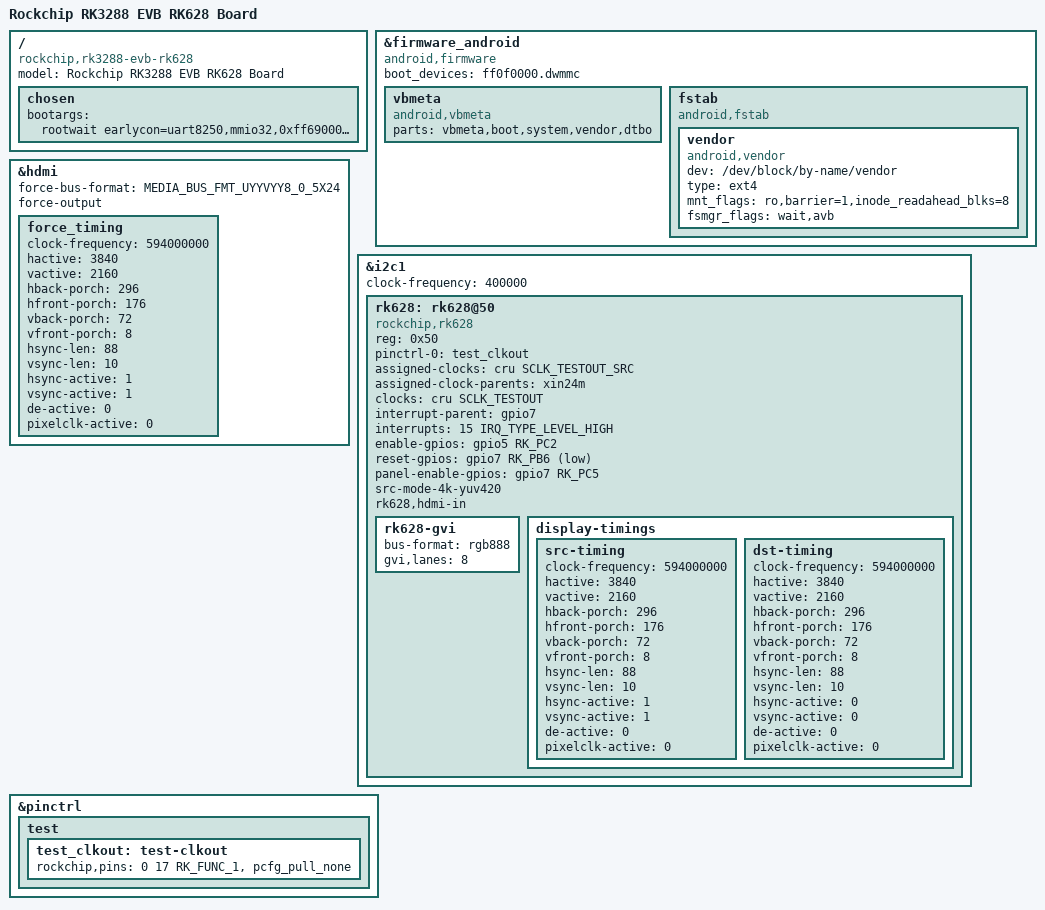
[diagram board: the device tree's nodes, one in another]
// SPDX-License-Identifier: (GPL-2.0+ OR MIT)
// Copyright (c) 2020 Fuzhou Rockchip Electronics Co., Ltd

/dts-v1/;
#include "rk3288-evb-rk628.dtsi"

/ {
	model = "Rockchip RK3288 EVB RK628 Board";
	compatible = "rockchip,rk3288-evb-rk628", "rockchip,rk3288";

	chosen {
		bootargs = "rootwait earlycon=uart8250,mmio32,0xff690000 vmalloc=496M swiotlb=1 console=ttyFIQ0 androidboot.baseband=N/A androidboot.veritymode=enforcing androidboot.hardware=rk30board androidboot.console=ttyFIQ0 init=/init kpti=0";
	};
};

&firmware_android {
	compatible = "android,firmware";
	boot_devices = "ff0f0000.dwmmc";

	vbmeta {
		compatible = "android,vbmeta";
		parts = "vbmeta,boot,system,vendor,dtbo";
	};

	fstab {
		compatible = "android,fstab";

		vendor {
			compatible = "android,vendor";
			dev = "/dev/block/by-name/vendor";
			type = "ext4";
			mnt_flags = "ro,barrier=1,inode_readahead_blks=8";
			fsmgr_flags = "wait,avb";
		};
	};
};

&hdmi {
	status = "okay";
	force-bus-format = <MEDIA_BUS_FMT_UYYVYY8_0_5X24>;
	force-output;
	force_timing {
		clock-frequency = <594000000>;
		hactive = <3840>;
		vactive = <2160>;
		hback-porch = <296>;
		hfront-porch = <176>;
		vback-porch = <72>;
		vfront-porch = <8>;
		hsync-len = <88>;
		vsync-len = <10>;
		hsync-active = <1>;
		vsync-active = <1>;
		de-active = <0>;
		pixelclk-active = <0>;
	};
};

&i2c1 {
	clock-frequency = <400000>;
	status = "okay";

	rk628: rk628@50 {
		compatible = "rockchip,rk628";
		reg = <0x50>;
		pinctrl-names = "default";
		pinctrl-0 = <&test_clkout>;
		assigned-clocks = <&cru SCLK_TESTOUT_SRC>;
		assigned-clock-parents = <&xin24m>;
		clocks = <&cru SCLK_TESTOUT>;
		clock-names = "soc_24M";
		interrupt-parent = <&gpio7>;
		interrupts = <15 IRQ_TYPE_LEVEL_HIGH>;
		enable-gpios = <&gpio5 RK_PC2 GPIO_ACTIVE_HIGH>;
		reset-gpios = <&gpio7 RK_PB6 GPIO_ACTIVE_LOW>;
		panel-enable-gpios = <&gpio7 RK_PC5 GPIO_ACTIVE_HIGH>;
		status = "okay";

		src-mode-4k-yuv420;
		rk628,hdmi-in;
		rk628-gvi {
			/* "rgb666"
			 * "rgb888"
			 * "rgb101010"
			 * "yuyv8"
			 * "yuyv10"
			 */
			bus-format = "rgb888";
			gvi,lanes = <8>;
			//"rockchip,division-mode";
			//"rockchip, gvi-frm-rst";
			status = "okay";
		};

		display-timings {
			src-timing {
				clock-frequency = <594000000>;
				hactive = <3840>;
				vactive = <2160>;
				hback-porch = <296>;
				hfront-porch = <176>;
				vback-porch = <72>;
				vfront-porch = <8>;
				hsync-len = <88>;
				vsync-len = <10>;
				hsync-active = <1>;
				vsync-active = <1>;
				de-active = <0>;
				pixelclk-active = <0>;
			};

			dst-timing {
				clock-frequency = <594000000>;
				hactive = <3840>;
				vactive = <2160>;
				hback-porch = <296>;
				hfront-porch = <176>;
				vback-porch = <72>;
				vfront-porch = <8>;
				hsync-len = <88>;
				vsync-len = <10>;
				hsync-active = <0>;
				vsync-active = <0>;
				de-active = <0>;
				pixelclk-active = <0>;
			};
	    };
	};
};

&pinctrl {
	test {
		test_clkout: test-clkout {
			rockchip,pins = <0 17 RK_FUNC_1 &pcfg_pull_none>;
		};
	};
};
